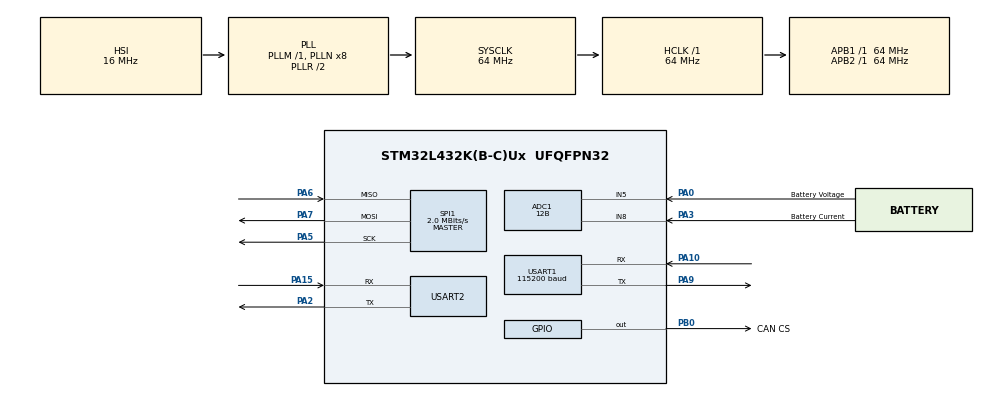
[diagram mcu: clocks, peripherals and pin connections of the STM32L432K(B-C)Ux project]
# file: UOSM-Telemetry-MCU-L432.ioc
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ADC1.Channel-0\#ChannelRegularConversion=ADC_CHANNEL_5
ADC1.Channel-1\#ChannelRegularConversion=ADC_CHANNEL_8
ADC1.ClockPrescaler=ADC_CLOCK_ASYNC_DIV1
ADC1.ContinuousConvMode=DISABLE
ADC1.DMAContinuousRequests=ENABLE
ADC1.EOCSelection=ADC_EOC_SEQ_CONV
ADC1.ExternalTrigConv=ADC_EXTERNALTRIG_T1_TRGO
ADC1.NbrOfConversion=2
ADC1.NbrOfConversionFlag=1
ADC1.OffsetNumber-0\#ChannelRegularConversion=ADC_OFFSET_NONE
ADC1.OffsetNumber-1\#ChannelRegularConversion=ADC_OFFSET_NONE
ADC1.Overrun=ADC_OVR_DATA_OVERWRITTEN
ADC1.OversamplingMode=DISABLE
ADC1.Rank-0\#ChannelRegularConversion=1
ADC1.Rank-1\#ChannelRegularConversion=2
ADC1.Resolution=ADC_RESOLUTION_12B
ADC1.SamplingTime-0\#ChannelRegularConversion=ADC_SAMPLETIME_2CYCLES_5
ADC1.SamplingTime-1\#ChannelRegularConversion=ADC_SAMPLETIME_2CYCLES_5
ADC1.master=1
Dma.ADC1.0.Direction=DMA_PERIPH_TO_MEMORY
Dma.ADC1.0.Instance=DMA1_Channel1
Dma.ADC1.0.MemDataAlignment=DMA_MDATAALIGN_HALFWORD
Dma.ADC1.0.MemInc=DMA_MINC_ENABLE
Dma.ADC1.0.Mode=DMA_CIRCULAR
Dma.ADC1.0.PeriphDataAlignment=DMA_PDATAALIGN_HALFWORD
Dma.ADC1.0.PeriphInc=DMA_PINC_DISABLE
Dma.ADC1.0.Priority=DMA_PRIORITY_LOW
Dma.Request0=ADC1
FREERTOS.Tasks01=defaultTask,24,128,StartDefaultTask,Default,NULL,Dynamic,NULL,NULL
FREERTOS.configTOTAL_HEAP_SIZE=30000
FREERTOS.configUSE_NEWLIB_REENTRANT=1
Mcu.Family=STM32L4
Mcu.Name=STM32L432K(B-C)Ux
Mcu.Package=UFQFPN32
NVIC.DMA1_Channel1_IRQn=true\:5\:0\:false\:false\:true\:true\:false\:true\:true
NVIC.PriorityGroup=NVIC_PRIORITYGROUP_4
PA0.GPIO_Label=Battery Voltage
PA0.Signal=ADCx_IN5
PA10.Mode=Asynchronous
PA10.Signal=USART1_RX
PA15\ (JTDI).Mode=Asynchronous
PA15\ (JTDI).Signal=USART2_RX
PA2.Mode=Asynchronous
PA2.Signal=USART2_TX
PA3.GPIO_Label=Battery Current
PA3.Signal=ADCx_IN8
PA5.Mode=Full_Duplex_Master
PA5.Signal=SPI1_SCK
PA6.Mode=Full_Duplex_Master
PA6.Signal=SPI1_MISO
PA7.Mode=Full_Duplex_Master
PA7.Signal=SPI1_MOSI
PA9.Mode=Asynchronous
PA9.Signal=USART1_TX
PB0.GPIO_Label=CAN CS
PB0.Signal=GPIO_Output
ProjectManager.HeapSize=0x200
ProjectManager.StackSize=0x400
ProjectManager.TargetToolchain=STM32CubeIDE
RCC.ADCFreq_Value=64000000
RCC.AHBFreq_Value=64000000
RCC.APB1Freq_Value=64000000
RCC.APB1TimFreq_Value=64000000
RCC.APB2Freq_Value=64000000
RCC.APB2TimFreq_Value=64000000
RCC.CortexFreq_Value=64000000
RCC.HCLKFreq_Value=64000000
RCC.HSE_VALUE=8000000
RCC.HSI48_VALUE=48000000
RCC.HSI_VALUE=16000000
RCC.LSE_VALUE=32768
RCC.MSI_VALUE=4000000
RCC.PLLSourceVirtual=RCC_PLLSOURCE_HSI
RCC.SYSCLKFreq_VALUE=64000000
RCC.SYSCLKSource=RCC_SYSCLKSOURCE_PLLCLK
RCC.USBFreq_Value=64000000
RCC.VCOOutputFreq_Value=128000000
RTC.Format=RTC_FORMAT_BIN
SH.ADCx_IN5.0=ADC1_IN5,IN5-Single-Ended
SH.ADCx_IN8.0=ADC1_IN8,IN8-Single-Ended
SPI1.BaudRatePrescaler=SPI_BAUDRATEPRESCALER_32
SPI1.CLKPhase=SPI_PHASE_2EDGE
SPI1.CLKPolarity=SPI_POLARITY_HIGH
SPI1.CalculateBaudRate=2.0 MBits/s
SPI1.DataSize=SPI_DATASIZE_8BIT
SPI1.Direction=SPI_DIRECTION_2LINES
SPI1.Mode=SPI_MODE_MASTER
SPI1.VirtualType=VM_MASTER
TIM1.AutoReloadPreload=TIM_AUTORELOAD_PRELOAD_ENABLE
TIM1.ClockDivision=TIM_CLOCKDIVISION_DIV1
TIM1.Prescaler=32
TIM1.TIM_MasterOutputTrigger=TIM_TRGO_UPDATE
USART1.BaudRate=115200
USART1.VirtualMode-Asynchronous=VM_ASYNC
USART2.VirtualMode-Asynchronous=VM_ASYNC
VP_ADC1_Vref_Input.Mode=IN-Vrefint
VP_FREERTOS_VS_CMSIS_V2.Mode=CMSIS_V2
VP_RTC_VS_RTC_Activate.Mode=RTC_Enabled
VP_RTC_VS_RTC_Calendar.Mode=RTC_Calendar
VP_TIM1_VS_ClockSourceINT.Mode=Internal
board=custom

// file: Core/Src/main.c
/* USER CODE BEGIN Header */
/**
  ******************************************************************************
  * @file           : main.c
  * @brief          : Main program body
  ******************************************************************************
  * @attention
  *
  * Copyright (c) 2023 STMicroelectronics.
  * All rights reserved.
  *
  * This software is licensed under terms that can be found in the LICENSE file
  * in the root directory of this software component.
  * If no LICENSE file comes with this software, it is provided AS-IS.
  *
  ******************************************************************************
  */
/* USER CODE END Header */
#include "main.h"
#include "cmsis_os.h"

/* USER CODE BEGIN Includes */
#include "TaskManager.h"
/* USER CODE END Includes */

ADC_HandleTypeDef hadc1;
DMA_HandleTypeDef hdma_adc1;

RTC_HandleTypeDef hrtc;

SPI_HandleTypeDef hspi1;

TIM_HandleTypeDef htim1;

UART_HandleTypeDef huart1;
UART_HandleTypeDef huart2;

/* Definitions for defaultTask */
osThreadId_t defaultTaskHandle;
const osThreadAttr_t defaultTask_attributes = {
  .name = "defaultTask",
  .stack_size = 128 * 4,
  .priority = (osPriority_t) osPriorityNormal,
};

void SystemClock_Config(void);
static void MX_GPIO_Init(void);
static void MX_DMA_Init(void);
static void MX_USART2_UART_Init(void);
static void MX_SPI1_Init(void);
static void MX_USART1_UART_Init(void);
static void MX_RTC_Init(void);
static void MX_ADC1_Init(void);
static void MX_TIM1_Init(void);
void StartDefaultTask(void *argument);

int main(void)
{

  /* MCU Configuration--------------------------------------------------------*/

  /* Reset of all peripherals, Initializes the Flash interface and the Systick. */
  HAL_Init();

  /* Configure the system clock */
  SystemClock_Config();

  /* Initialize all configured peripherals */
  MX_GPIO_Init();
  MX_DMA_Init();
  MX_USART2_UART_Init();
  MX_SPI1_Init();
  MX_USART1_UART_Init();
  MX_RTC_Init();
  MX_ADC1_Init();
  MX_TIM1_Init();

  /* Init scheduler */
  osKernelInitialize();

  /* Create the thread(s) */
  /* creation of defaultTask */
  defaultTaskHandle = osThreadNew(StartDefaultTask, NULL, &defaultTask_attributes);

  /* USER CODE BEGIN RTOS_THREADS */
  /*+----------------------------------------------+
  	|                                              |
  	|       !!!!!!!IMPORTANT!!!!                   |
  	|RunTaskManager() is the only function to run! |
  	|                                              |
  	+----------------------------------------------+
  */
  RunTaskManager();
  /* USER CODE END RTOS_THREADS */

  /* Start scheduler */
  osKernelStart();
  /* We should never get here as control is now taken by the scheduler */
  /* Infinite loop */
  while (1)
  {

  }
}

void SystemClock_Config(void)
{
  RCC_OscInitTypeDef RCC_OscInitStruct = {0};
  RCC_ClkInitTypeDef RCC_ClkInitStruct = {0};

  /** Configure the main internal regulator output voltage
  */
  if (HAL_PWREx_ControlVoltageScaling(PWR_REGULATOR_VOLTAGE_SCALE1) != HAL_OK)
  {
    Error_Handler();
  }

  /** Initializes the RCC Oscillators according to the specified parameters
  * in the RCC_OscInitTypeDef structure.
  */
  RCC_OscInitStruct.OscillatorType = RCC_OSCILLATORTYPE_HSI|RCC_OSCILLATORTYPE_LSI;
  RCC_OscInitStruct.HSIState = RCC_HSI_ON;
  RCC_OscInitStruct.HSICalibrationValue = RCC_HSICALIBRATION_DEFAULT;
  RCC_OscInitStruct.LSIState = RCC_LSI_ON;
  RCC_OscInitStruct.PLL.PLLState = RCC_PLL_ON;
  RCC_OscInitStruct.PLL.PLLSource = RCC_PLLSOURCE_HSI;
  RCC_OscInitStruct.PLL.PLLM = 1;
  RCC_OscInitStruct.PLL.PLLN = 8;
  RCC_OscInitStruct.PLL.PLLP = RCC_PLLP_DIV7;
  RCC_OscInitStruct.PLL.PLLQ = RCC_PLLQ_DIV2;
  RCC_OscInitStruct.PLL.PLLR = RCC_PLLR_DIV2;
  if (HAL_RCC_OscConfig(&RCC_OscInitStruct) != HAL_OK)
  {
    Error_Handler();
  }

  /** Initializes the CPU, AHB and APB buses clocks
  */
  RCC_ClkInitStruct.ClockType = RCC_CLOCKTYPE_HCLK|RCC_CLOCKTYPE_SYSCLK
                              |RCC_CLOCKTYPE_PCLK1|RCC_CLOCKTYPE_PCLK2;
  RCC_ClkInitStruct.SYSCLKSource = RCC_SYSCLKSOURCE_PLLCLK;
  RCC_ClkInitStruct.AHBCLKDivider = RCC_SYSCLK_DIV1;
  RCC_ClkInitStruct.APB1CLKDivider = RCC_HCLK_DIV1;
  RCC_ClkInitStruct.APB2CLKDivider = RCC_HCLK_DIV1;

  if (HAL_RCC_ClockConfig(&RCC_ClkInitStruct, FLASH_LATENCY_3) != HAL_OK)
  {
    Error_Handler();
  }
}

static void MX_ADC1_Init(void)
{

  ADC_ChannelConfTypeDef sConfig = {0};

  /** Common config
  */
  hadc1.Instance = ADC1;
  hadc1.Init.ClockPrescaler = ADC_CLOCK_ASYNC_DIV1;
  hadc1.Init.Resolution = ADC_RESOLUTION_12B;
  hadc1.Init.DataAlign = ADC_DATAALIGN_RIGHT;
  hadc1.Init.ScanConvMode = ADC_SCAN_ENABLE;
  hadc1.Init.EOCSelection = ADC_EOC_SEQ_CONV;
  hadc1.Init.LowPowerAutoWait = DISABLE;
  hadc1.Init.ContinuousConvMode = DISABLE;
  hadc1.Init.NbrOfConversion = 2;
  hadc1.Init.DiscontinuousConvMode = DISABLE;
  hadc1.Init.ExternalTrigConv = ADC_EXTERNALTRIG_T1_TRGO;
  hadc1.Init.ExternalTrigConvEdge = ADC_EXTERNALTRIGCONVEDGE_RISING;
  hadc1.Init.DMAContinuousRequests = ENABLE;
  hadc1.Init.Overrun = ADC_OVR_DATA_OVERWRITTEN;
  hadc1.Init.OversamplingMode = DISABLE;
  if (HAL_ADC_Init(&hadc1) != HAL_OK)
  {
    Error_Handler();
  }

  /** Configure Regular Channel
  */
  sConfig.Channel = ADC_CHANNEL_5;
  sConfig.Rank = ADC_REGULAR_RANK_1;
  sConfig.SamplingTime = ADC_SAMPLETIME_2CYCLES_5;
  sConfig.SingleDiff = ADC_SINGLE_ENDED;
  sConfig.OffsetNumber = ADC_OFFSET_NONE;
  sConfig.Offset = 0;
  if (HAL_ADC_ConfigChannel(&hadc1, &sConfig) != HAL_OK)
  {
    Error_Handler();
  }

  /** Configure Regular Channel
  */
  sConfig.Channel = ADC_CHANNEL_8;
  sConfig.Rank = ADC_REGULAR_RANK_2;
  if (HAL_ADC_ConfigChannel(&hadc1, &sConfig) != HAL_OK)
  {
    Error_Handler();
  }

}

static void MX_RTC_Init(void)
{

  RTC_TimeTypeDef sTime = {0};
  RTC_DateTypeDef sDate = {0};

  /** Initialize RTC Only
  */
  hrtc.Instance = RTC;
  hrtc.Init.HourFormat = RTC_HOURFORMAT_24;
  hrtc.Init.AsynchPrediv = 127;
  hrtc.Init.SynchPrediv = 255;
  hrtc.Init.OutPut = RTC_OUTPUT_DISABLE;
  hrtc.Init.OutPutRemap = RTC_OUTPUT_REMAP_NONE;
  hrtc.Init.OutPutPolarity = RTC_OUTPUT_POLARITY_HIGH;
  hrtc.Init.OutPutType = RTC_OUTPUT_TYPE_OPENDRAIN;
  if (HAL_RTC_Init(&hrtc) != HAL_OK)
  {
    Error_Handler();
  }

  /** Initialize RTC and set the Time and Date
  */
  sTime.Hours = 0;
  sTime.Minutes = 0;
  sTime.Seconds = 0;
  sTime.DayLightSaving = RTC_DAYLIGHTSAVING_NONE;
  sTime.StoreOperation = RTC_STOREOPERATION_RESET;
  if (HAL_RTC_SetTime(&hrtc, &sTime, RTC_FORMAT_BIN) != HAL_OK)
  {
    Error_Handler();
  }
  sDate.WeekDay = RTC_WEEKDAY_MONDAY;
  sDate.Month = RTC_MONTH_JANUARY;
  sDate.Date = 1;
  sDate.Year = 0;

  if (HAL_RTC_SetDate(&hrtc, &sDate, RTC_FORMAT_BIN) != HAL_OK)
  {
    Error_Handler();
  }

}

static void MX_SPI1_Init(void)
{

  /* SPI1 parameter configuration*/
  hspi1.Instance = SPI1;
  hspi1.Init.Mode = SPI_MODE_MASTER;
  hspi1.Init.Direction = SPI_DIRECTION_2LINES;
  hspi1.Init.DataSize = SPI_DATASIZE_8BIT;
  hspi1.Init.CLKPolarity = SPI_POLARITY_HIGH;
  hspi1.Init.CLKPhase = SPI_PHASE_2EDGE;
  hspi1.Init.NSS = SPI_NSS_SOFT;
  hspi1.Init.BaudRatePrescaler = SPI_BAUDRATEPRESCALER_32;
  hspi1.Init.FirstBit = SPI_FIRSTBIT_MSB;
  hspi1.Init.TIMode = SPI_TIMODE_DISABLE;
  hspi1.Init.CRCCalculation = SPI_CRCCALCULATION_DISABLE;
  hspi1.Init.CRCPolynomial = 7;
  hspi1.Init.CRCLength = SPI_CRC_LENGTH_DATASIZE;
  hspi1.Init.NSSPMode = SPI_NSS_PULSE_DISABLE;
  if (HAL_SPI_Init(&hspi1) != HAL_OK)
  {
    Error_Handler();
  }

}

static void MX_TIM1_Init(void)
{

  TIM_ClockConfigTypeDef sClockSourceConfig = {0};
  TIM_MasterConfigTypeDef sMasterConfig = {0};

  htim1.Instance = TIM1;
  htim1.Init.Prescaler = 32;
  htim1.Init.CounterMode = TIM_COUNTERMODE_UP;
  htim1.Init.Period = 65535;
  htim1.Init.ClockDivision = TIM_CLOCKDIVISION_DIV1;
  htim1.Init.RepetitionCounter = 0;
  htim1.Init.AutoReloadPreload = TIM_AUTORELOAD_PRELOAD_ENABLE;
  if (HAL_TIM_Base_Init(&htim1) != HAL_OK)
  {
    Error_Handler();
  }
  sClockSourceConfig.ClockSource = TIM_CLOCKSOURCE_INTERNAL;
  if (HAL_TIM_ConfigClockSource(&htim1, &sClockSourceConfig) != HAL_OK)
  {
    Error_Handler();
  }
  sMasterConfig.MasterOutputTrigger = TIM_TRGO_UPDATE;
  sMasterConfig.MasterOutputTrigger2 = TIM_TRGO2_RESET;
  sMasterConfig.MasterSlaveMode = TIM_MASTERSLAVEMODE_DISABLE;
  if (HAL_TIMEx_MasterConfigSynchronization(&htim1, &sMasterConfig) != HAL_OK)
  {
    Error_Handler();
  }

}

static void MX_USART1_UART_Init(void)
{

  huart1.Instance = USART1;
  huart1.Init.BaudRate = 115200;
  huart1.Init.WordLength = UART_WORDLENGTH_8B;
  huart1.Init.StopBits = UART_STOPBITS_1;
  huart1.Init.Parity = UART_PARITY_NONE;
  huart1.Init.Mode = UART_MODE_TX_RX;
  huart1.Init.HwFlowCtl = UART_HWCONTROL_NONE;
  huart1.Init.OverSampling = UART_OVERSAMPLING_16;
  huart1.Init.OneBitSampling = UART_ONE_BIT_SAMPLE_DISABLE;
  huart1.AdvancedInit.AdvFeatureInit = UART_ADVFEATURE_NO_INIT;
  if (HAL_UART_Init(&huart1) != HAL_OK)
  {
    Error_Handler();
  }

}

static void MX_USART2_UART_Init(void)
{

  huart2.Instance = USART2;
  huart2.Init.BaudRate = 115200;
  huart2.Init.WordLength = UART_WORDLENGTH_8B;
  huart2.Init.StopBits = UART_STOPBITS_1;
  huart2.Init.Parity = UART_PARITY_NONE;
  huart2.Init.Mode = UART_MODE_TX_RX;
  huart2.Init.HwFlowCtl = UART_HWCONTROL_NONE;
  huart2.Init.OverSampling = UART_OVERSAMPLING_16;
  huart2.Init.OneBitSampling = UART_ONE_BIT_SAMPLE_DISABLE;
  huart2.AdvancedInit.AdvFeatureInit = UART_ADVFEATURE_NO_INIT;
  if (HAL_UART_Init(&huart2) != HAL_OK)
  {
    Error_Handler();
  }

}

static void MX_DMA_Init(void)
{

  /* DMA controller clock enable */
  __HAL_RCC_DMA1_CLK_ENABLE();

  /* DMA interrupt init */
  /* DMA1_Channel1_IRQn interrupt configuration */
  HAL_NVIC_SetPriority(DMA1_Channel1_IRQn, 5, 0);
  HAL_NVIC_EnableIRQ(DMA1_Channel1_IRQn);

}

static void MX_GPIO_Init(void)
{
  GPIO_InitTypeDef GPIO_InitStruct = {0};

  /* GPIO Ports Clock Enable */
  __HAL_RCC_GPIOA_CLK_ENABLE();
  __HAL_RCC_GPIOB_CLK_ENABLE();

  /*Configure GPIO pin Output Level */
  HAL_GPIO_WritePin(CAN_CS_GPIO_Port, CAN_CS_Pin, GPIO_PIN_RESET);

  /*Configure GPIO pin : CAN_CS_Pin */
  GPIO_InitStruct.Pin = CAN_CS_Pin;
  GPIO_InitStruct.Mode = GPIO_MODE_OUTPUT_PP;
  GPIO_InitStruct.Pull = GPIO_NOPULL;
  GPIO_InitStruct.Speed = GPIO_SPEED_FREQ_LOW;
  HAL_GPIO_Init(CAN_CS_GPIO_Port, &GPIO_InitStruct);

}

void StartDefaultTask(void *argument)
{
  for(;;)
  {
    osDelay(1);
  }
}

void Error_Handler(void)
{
  __disable_irq();
  while (1)
  {
  }
}
